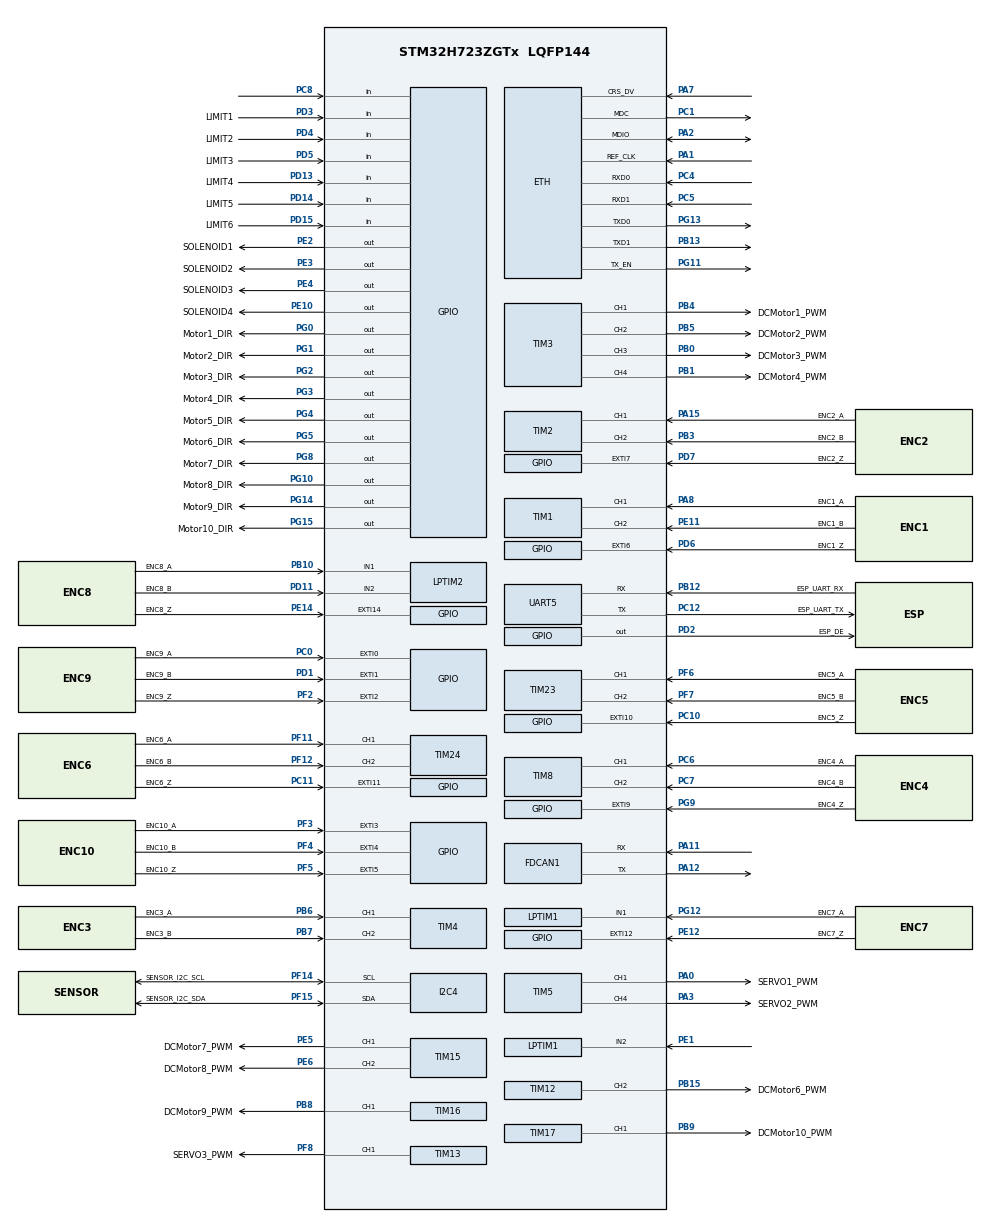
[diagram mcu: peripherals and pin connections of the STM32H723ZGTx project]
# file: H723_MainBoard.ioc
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CORTEX_M7.default_mode_Activation=1
Dma.Request0=UART5_RX
Dma.UART5_RX.0.Direction=DMA_PERIPH_TO_MEMORY
Dma.UART5_RX.0.EventEnable=DISABLE
Dma.UART5_RX.0.FIFOMode=DMA_FIFOMODE_DISABLE
Dma.UART5_RX.0.Instance=DMA1_Stream0
Dma.UART5_RX.0.MemDataAlignment=DMA_MDATAALIGN_BYTE
Dma.UART5_RX.0.MemInc=DMA_MINC_ENABLE
Dma.UART5_RX.0.Mode=DMA_CIRCULAR
Dma.UART5_RX.0.PeriphDataAlignment=DMA_PDATAALIGN_BYTE
Dma.UART5_RX.0.PeriphInc=DMA_PINC_DISABLE
Dma.UART5_RX.0.Polarity=HAL_DMAMUX_REQ_GEN_RISING
Dma.UART5_RX.0.Priority=DMA_PRIORITY_LOW
Dma.UART5_RX.0.RequestNumber=1
Dma.UART5_RX.0.SignalID=NONE
Dma.UART5_RX.0.SyncEnable=DISABLE
Dma.UART5_RX.0.SyncPolarity=HAL_DMAMUX_SYNC_NO_EVENT
Dma.UART5_RX.0.SyncRequestNumber=1
Dma.UART5_RX.0.SyncSignalID=NONE
ETH.MediaInterface=HAL_ETH_RMII_MODE
FDCAN1.CalculateBaudRateNominal=250000
FDCAN1.CalculateTimeBitNominal=4000
FDCAN1.CalculateTimeQuantumNominal=250.0
FDCAN1.NominalPrescaler=12
FDCAN1.NominalSyncJumpWidth=2
FDCAN1.NominalTimeSeg1=13
FDCAN1.NominalTimeSeg2=2
FDCAN1.RxFifo0ElmtsNbr=16
FDCAN1.StdFiltersNbr=1
I2C4.Timing=0x20303E5D
Mcu.Family=STM32H7
Mcu.Name=STM32H723ZGTx
Mcu.Package=LQFP144
NUCLEO-H723ZG.BUTTON=1
NUCLEO-H723ZG.LD1=false
NUCLEO-H723ZG.LD2=true
NUCLEO-H723ZG.LD3=true
NUCLEO-H723ZG.VCP=true
NVIC.DMA1_Stream0_IRQn=true\:0\:0\:false\:false\:true\:false\:true\:true
NVIC.EXTI15_10_IRQn=true\:0\:0\:false\:false\:true\:false\:true\:true
NVIC.PriorityGroup=NVIC_PRIORITYGROUP_4
NVIC.UART5_IRQn=true\:0\:0\:false\:false\:true\:true\:true\:true
PA0.GPIO_Label=SERVO1_PWM
PA0.Signal=S_TIM5_CH1
PA1.Mode=RMII
PA1.Signal=ETH_REF_CLK
PA11.Mode=FDCAN_Activate
PA11.Signal=FDCAN1_RX
PA12.Mode=FDCAN_Activate
PA12.Signal=FDCAN1_TX
PA13(JTMS/SWDIO).GPIO_Label=SWDIO
PA13(JTMS/SWDIO).Mode=Serial_Wire
PA13(JTMS/SWDIO).Signal=DEBUG_JTMS-SWDIO
PA14(JTCK/SWCLK).GPIO_Label=SWCLK
PA14(JTCK/SWCLK).Mode=Serial_Wire
PA14(JTCK/SWCLK).Signal=DEBUG_JTCK-SWCLK
PA15(JTDI).GPIO_Label=ENC2_A
PA15(JTDI).Signal=S_TIM2_CH1_ETR
PA2.Mode=RMII
PA2.Signal=ETH_MDIO
PA3.GPIO_Label=SERVO2_PWM
PA3.Signal=S_TIM5_CH4
PA7.Mode=RMII
PA7.Signal=ETH_CRS_DV
PA8.GPIO_Label=ENC1_A
PA8.Signal=S_TIM1_CH1
PB0.GPIO_Label=DCMotor3_PWM
PB0.Signal=S_TIM3_CH3
PB1.GPIO_Label=DCMotor4_PWM
PB1.Signal=S_TIM3_CH4
PB10.GPIO_Label=ENC8_A
PB10.Mode=Encoder_mode_occur1
PB10.Signal=LPTIM2_IN1
PB12.GPIO_Label=ESP_UART_RX
PB12.Mode=Asynchronous
PB12.Signal=UART5_RX
PB13.Mode=RMII
PB13.Signal=ETH_TXD1
PB15.GPIO_Label=DCMotor6_PWM
PB15.Signal=S_TIM12_CH2
PB3(JTDO/TRACESWO).GPIO_Label=ENC2_B
PB3(JTDO/TRACESWO).Signal=S_TIM2_CH2
PB4(NJTRST).GPIO_Label=DCMotor1_PWM
PB4(NJTRST).Signal=S_TIM3_CH1
PB5.GPIO_Label=DCMotor2_PWM
PB5.Signal=S_TIM3_CH2
PB6.GPIO_Label=ENC3_A
PB6.Signal=S_TIM4_CH1
PB7.GPIO_Label=ENC3_B
PB7.Signal=S_TIM4_CH2
PB8.GPIO_Label=DCMotor9_PWM
PB8.Signal=S_TIM16_CH1
PB9.GPIO_Label=DCMotor10_PWM
PB9.Signal=S_TIM17_CH1
PC0.GPIO_Label=ENC9_A
PC0.Signal=GPXTI0
PC1.Mode=RMII
PC1.Signal=ETH_MDC
PC10.GPIO_Label=ENC5_Z
PC10.Signal=GPXTI10
PC11.GPIO_Label=ENC6_Z
PC11.Signal=GPXTI11
PC12.GPIO_Label=ESP_UART_TX
PC12.Mode=Asynchronous
PC12.Signal=UART5_TX
PC14-OSC32_IN.Mode=LSE-External-Oscillator
PC14-OSC32_IN.Signal=RCC_OSC32_IN
PC15-OSC32_OUT.Mode=LSE-External-Oscillator
PC15-OSC32_OUT.Signal=RCC_OSC32_OUT
PC4.Mode=RMII
PC4.Signal=ETH_RXD0
PC5.Mode=RMII
PC5.Signal=ETH_RXD1
PC6.GPIO_Label=ENC4_A
PC6.Signal=S_TIM8_CH1
PC7.GPIO_Label=ENC4_B
PC7.Signal=S_TIM8_CH2
PC8.Signal=GPIO_Input
PD1.GPIO_Label=ENC9_B
PD1.Signal=GPXTI1
PD11.GPIO_Label=ENC8_B
PD11.Mode=Encoder_mode_occur1
PD11.Signal=LPTIM2_IN2
PD13.GPIO_Label=LIMIT4
PD13.GPIO_PuPd=GPIO_PULLUP
PD13.Signal=GPIO_Input
PD14.GPIO_Label=LIMIT5
PD14.GPIO_PuPd=GPIO_PULLUP
PD14.Signal=GPIO_Input
PD15.GPIO_Label=LIMIT6
PD15.GPIO_PuPd=GPIO_PULLUP
PD15.Signal=GPIO_Input
PD2.GPIO_Label=ESP_DE
PD2.Signal=GPIO_Output
PD3.GPIO_Label=LIMIT1
PD3.GPIO_PuPd=GPIO_PULLUP
PD3.Signal=GPIO_Input
PD4.GPIO_Label=LIMIT2
PD4.GPIO_PuPd=GPIO_PULLUP
PD4.Signal=GPIO_Input
PD5.GPIO_Label=LIMIT3
PD5.GPIO_PuPd=GPIO_PULLUP
PD5.Signal=GPIO_Input
PD6.GPIO_Label=ENC1_Z
PD6.GPIO_PuPd=GPIO_NOPULL
PD6.Signal=GPXTI6
PD7.GPIO_Label=ENC2_Z
PD7.Signal=GPXTI7
PD8.Signal=USART3_TX
PD9.Signal=USART3_RX
PE1.Mode=Encoder_mode_occur1
PE1.Signal=LPTIM1_IN2
PE10.GPIO_Label=SOLENOID4
PE10.Signal=GPIO_Output
PE11.GPIO_Label=ENC1_B
PE11.Signal=S_TIM1_CH2
PE12.GPIO_Label=ENC7_Z
PE12.Signal=GPXTI12
PE14.GPIO_Label=ENC8_Z
PE14.Signal=GPXTI14
PE2.GPIO_Label=SOLENOID1
PE2.Signal=GPIO_Output
PE3.GPIO_Label=SOLENOID2
PE3.Signal=GPIO_Output
PE4.GPIO_Label=SOLENOID3
PE4.Signal=GPIO_Output
PE5.GPIO_Label=DCMotor7_PWM
PE5.Signal=S_TIM15_CH1
PE6.GPIO_Label=DCMotor8_PWM
PE6.Signal=S_TIM15_CH2
PF11.GPIO_Label=ENC6_A
PF11.Mode=Encoder_Interface
PF11.Signal=TIM24_CH1
PF12.GPIO_Label=ENC6_B
PF12.Signal=S_TIM24_CH2
PF14.GPIO_Label=SENSOR_I2C_SCL
PF14.Mode=I2C
PF14.Signal=I2C4_SCL
PF15.GPIO_Label=SENSOR_I2C_SDA
PF15.Mode=I2C
PF15.Signal=I2C4_SDA
PF2.GPIO_Label=ENC9_Z
PF2.Signal=GPXTI2
PF3.GPIO_Label=ENC10_A
PF3.Signal=GPXTI3
PF4.GPIO_Label=ENC10_B
PF4.Signal=GPXTI4
PF5.GPIO_Label=ENC10_Z
PF5.Signal=GPXTI5
PF6.GPIO_Label=ENC5_A
PF6.Mode=Encoder_Interface
PF6.Signal=TIM23_CH1
PF7.GPIO_Label=ENC5_B
PF7.Signal=S_TIM23_CH2
PF8.GPIO_Label=SERVO3_PWM
PF8.Signal=S_TIM13_CH1
PG0.GPIO_Label=Motor1_DIR
PG0.Signal=GPIO_Output
PG1.GPIO_Label=Motor2_DIR
PG1.Signal=GPIO_Output
PG10.GPIO_Label=Motor8_DIR
PG10.Signal=GPIO_Output
PG11.Mode=RMII
PG11.Signal=ETH_TX_EN
PG12.GPIO_Label=ENC7_A
PG12.Mode=Encoder_mode_occur1
PG12.Signal=LPTIM1_IN1
PG13.Mode=RMII
PG13.Signal=ETH_TXD0
PG14.GPIO_Label=Motor9_DIR
PG14.Signal=GPIO_Output
PG15.GPIO_Label=Motor10_DIR
PG15.Signal=GPIO_Output
PG2.GPIO_Label=Motor3_DIR
PG2.Signal=GPIO_Output
PG3.GPIO_Label=Motor4_DIR
PG3.Signal=GPIO_Output
PG4.GPIO_Label=Motor5_DIR
PG4.Signal=GPIO_Output
PG5.GPIO_Label=Motor6_DIR
PG5.Signal=GPIO_Output
PG8.GPIO_Label=Motor7_DIR
PG8.Signal=GPIO_Output
PG9.GPIO_Label=ENC4_Z
PG9.Signal=GPXTI9
ProjectManager.HeapSize=0x200
ProjectManager.StackSize=0x400
ProjectManager.TargetToolchain=CMake
RCC.ADCFreq_Value=608000000
RCC.APB1Freq_Value=48000000
RCC.APB2Freq_Value=48000000
RCC.APB3Freq_Value=48000000
RCC.APB4Freq_Value=48000000
RCC.CortexFreq_Value=192000000
RCC.D1PPRE=RCC_APB3_DIV2
RCC.D2PPRE1=RCC_APB1_DIV2
RCC.D2PPRE2=RCC_APB2_DIV2
RCC.D3PPRE=RCC_APB4_DIV2
RCC.DIVM1=4
RCC.DIVM2=1
RCC.DIVN1=12
RCC.DIVN2=19
RCC.DIVP1=1
RCC.DIVQ1=4
RCC.HCLKFreq_Value=96000000
RCC.HPRE=RCC_HCLK_DIV2
RCC.HSE_VALUE=8000000
RCC.PLLFRACN=0
RCC.SYSCLKFreq_VALUE=192000000
RCC.SYSCLKSource=RCC_SYSCLKSOURCE_PLLCLK
RCC.USBCLockSelection=RCC_USBCLKSOURCE_HSI48
RCC.USBFreq_Value=48000000
SH.S_TIM12_CH2.0=TIM12_CH2,PWM Generation2 CH2
SH.S_TIM13_CH1.0=TIM13_CH1,PWM Generation1 CH1
SH.S_TIM15_CH1.0=TIM15_CH1,PWM Generation1 CH1
SH.S_TIM15_CH2.0=TIM15_CH2,PWM Generation2 CH2
SH.S_TIM16_CH1.0=TIM16_CH1,PWM Generation1 CH1
SH.S_TIM17_CH1.0=TIM17_CH1,PWM Generation1 CH1
SH.S_TIM1_CH1.0=TIM1_CH1,Encoder_Interface
SH.S_TIM1_CH2.0=TIM1_CH2,Encoder_Interface
SH.S_TIM23_CH2.0=TIM23_CH2,Encoder_Interface
SH.S_TIM24_CH2.0=TIM24_CH2,Encoder_Interface
SH.S_TIM2_CH1_ETR.0=TIM2_CH1,Encoder_Interface
SH.S_TIM2_CH2.0=TIM2_CH2,Encoder_Interface
SH.S_TIM3_CH1.0=TIM3_CH1,PWM Generation1 CH1
SH.S_TIM3_CH2.0=TIM3_CH2,PWM Generation2 CH2
SH.S_TIM3_CH3.0=TIM3_CH3,PWM Generation3 CH3
SH.S_TIM3_CH4.0=TIM3_CH4,PWM Generation4 CH4
SH.S_TIM4_CH1.0=TIM4_CH1,Encoder_Interface
SH.S_TIM4_CH2.0=TIM4_CH2,Encoder_Interface
SH.S_TIM5_CH1.0=TIM5_CH1,PWM Generation1 CH1
SH.S_TIM5_CH4.0=TIM5_CH4,PWM Generation4 CH4
SH.S_TIM8_CH1.0=TIM8_CH1,Encoder_Interface
SH.S_TIM8_CH2.0=TIM8_CH2,Encoder_Interface
TIM12.Channel-PWM\ Generation1\ CH1=TIM_CHANNEL_1
TIM12.Channel-PWM\ Generation2\ CH2=TIM_CHANNEL_2
TIM13.Channel=TIM_CHANNEL_1
TIM15.Channel-PWM\ Generation1\ CH1=TIM_CHANNEL_1
TIM15.Channel-PWM\ Generation2\ CH2=TIM_CHANNEL_2
TIM16.Channel=TIM_CHANNEL_1
TIM17.Channel=TIM_CHANNEL_1
TIM3.Channel-PWM\ Generation1\ CH1=TIM_CHANNEL_1
TIM3.Channel-PWM\ Generation2\ CH2=TIM_CHANNEL_2
TIM3.Channel-PWM\ Generation3\ CH3=TIM_CHANNEL_3
TIM3.Channel-PWM\ Generation4\ CH4=TIM_CHANNEL_4
TIM5.Channel-PWM\ Generation1\ CH1=TIM_CHANNEL_1
TIM5.Channel-PWM\ Generation4\ CH4=TIM_CHANNEL_4
VP_MEMORYMAP_VS_MEMORYMAP.Mode=CurAppReg
VP_NUCLEO-H723ZG_VS_BSP_COMMON.Mode=COMMON
VP_TIM13_VS_ClockSourceINT.Mode=Enable_Timer
VP_TIM16_VS_ClockSourceINT.Mode=Enable_Timer
VP_TIM17_VS_ClockSourceINT.Mode=Enable_Timer
board=NUCLEO-H723ZG

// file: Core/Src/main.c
/* USER CODE BEGIN Header */
/**
  ******************************************************************************
  * @file           : main.c
  * @brief          : Main program body
  ******************************************************************************
  * @attention
  *
  * Copyright (c) 2026 STMicroelectronics.
  * All rights reserved.
  *
  * This software is licensed under terms that can be found in the LICENSE file
  * in the root directory of this software component.
  * If no LICENSE file comes with this software, it is provided AS-IS.
  *
  ******************************************************************************
  */
/* USER CODE END Header */
#include "main.h"
#include "dma.h"
#include "eth.h"
#include "fdcan.h"
#include "i2c.h"
#include "lptim.h"
#include "tim.h"
#include "usart.h"
#include "gpio.h"

COM_InitTypeDef BspCOMInit;

/* USER CODE BEGIN PV */

volatile uint32_t can_rx_count = 0;
volatile uint32_t can_rx_id = 0;
volatile uint32_t can_rx_dlc = 0;
volatile uint8_t can_rx_data[8] = {0};
volatile uint32_t can_psr = 0;
volatile uint32_t can_ecr = 0;
volatile uint32_t can_clock = 0;
volatile uint32_t can_error_events = 0;
volatile uint32_t can_last_error = 0;
volatile uint32_t can_rx_low_samples = 0;
volatile uint32_t can_rx_sampled_edges = 0;
/* USER CODE END PV */

void SystemClock_Config(void);
static void MPU_Config(void);

int main(void)
{

  /* MPU Configuration--------------------------------------------------------*/
  MPU_Config();

  /* MCU Configuration--------------------------------------------------------*/

  /* Reset of all peripherals, Initializes the Flash interface and the Systick. */
  HAL_Init();

  /* Configure the system clock */
  SystemClock_Config();

  /* Initialize all configured peripherals */
  MX_GPIO_Init();
  MX_DMA_Init();
  MX_ETH_Init();
  MX_TIM3_Init();
  MX_TIM12_Init();
  MX_TIM15_Init();
  MX_TIM16_Init();
  MX_I2C4_Init();
  MX_LPTIM2_Init();
  MX_TIM1_Init();
  MX_TIM2_Init();
  MX_TIM4_Init();
  MX_TIM5_Init();
  MX_TIM8_Init();
  MX_TIM13_Init();
  MX_TIM17_Init();
  MX_TIM23_Init();
  MX_TIM24_Init();
  MX_UART5_Init();
  MX_FDCAN1_Init();
  /* USER CODE BEGIN 2 */

FDCAN_FilterTypeDef filter = {0};

filter.IdType = FDCAN_STANDARD_ID;
filter.FilterIndex = 0;
filter.FilterType = FDCAN_FILTER_MASK;
filter.FilterConfig = FDCAN_FILTER_TO_RXFIFO0;
filter.FilterID1 = 0x000;
filter.FilterID2 = 0x000;

if (HAL_FDCAN_ConfigFilter(&hfdcan1, &filter) != HAL_OK)
{
    Error_Handler();
}
if (HAL_FDCAN_ConfigGlobalFilter(&hfdcan1,
                                 FDCAN_REJECT,
                                 FDCAN_REJECT,
                                 FDCAN_REJECT_REMOTE,
                                 FDCAN_REJECT_REMOTE) != HAL_OK)
{
    Error_Handler();
}
if (HAL_FDCAN_Start(&hfdcan1) != HAL_OK)
{
    Error_Handler();
}

  /* USER CODE END 2 */

  /* Initialize leds */
  BSP_LED_Init(LED_YELLOW);
  BSP_LED_Init(LED_RED);

  /* Initialize USER push-button, will be used to trigger an interrupt each time it's pressed.*/
  BSP_PB_Init(BUTTON_USER, BUTTON_MODE_EXTI);

  /* Initialize COM1 port (115200, 8 bits (7-bit data + 1 stop bit), no parity */
  BspCOMInit.BaudRate   = 115200;
  BspCOMInit.WordLength = COM_WORDLENGTH_8B;
  BspCOMInit.StopBits   = COM_STOPBITS_1;
  BspCOMInit.Parity     = COM_PARITY_NONE;
  BspCOMInit.HwFlowCtl  = COM_HWCONTROL_NONE;
  if (BSP_COM_Init(COM1, &BspCOMInit) != BSP_ERROR_NONE)
  {
    Error_Handler();
  }

  /* Infinite loop */
  /* USER CODE BEGIN WHILE */
  /* CAN serial monitor: ST-LINK virtual COM, USART3 PD8/PD9. */
  setvbuf(stdout, NULL, _IONBF, 0);
  printf("\r\nH723 CAN serial monitor: Classic CAN, Normal, 250000 bps\r\n");
  printf("Serial: 115200 8N1, no flow control; CAN RX: PA11, TX: PA12\r\n");
  uint32_t last_rx_print = 0;
  uint32_t last_printed_count = 0;
  uint32_t last_status_print = 0;
  uint32_t last_rx_level = (GPIOA->IDR & GPIO_PIN_11) != 0U;
  while (1)
  {

    /* USER CODE END WHILE */

    /* USER CODE BEGIN 3 */
    /* Passive sampling: this is not a complete waveform capture. */
    uint32_t rx_level = (GPIOA->IDR & GPIO_PIN_11) != 0U;
    if (rx_level == 0U && can_rx_low_samples != UINT32_MAX)
    {
      can_rx_low_samples++;
    }
    if (rx_level != last_rx_level && can_rx_sampled_edges != UINT32_MAX)
    {
      can_rx_sampled_edges++;
    }
    last_rx_level = rx_level;

    if (HAL_FDCAN_GetRxFifoFillLevel(&hfdcan1, FDCAN_RX_FIFO0) > 0U)
    {
      FDCAN_RxHeaderTypeDef rxHeader;
      uint8_t rxData[8] = {0};
      if (HAL_FDCAN_GetRxMessage(&hfdcan1, FDCAN_RX_FIFO0,
                                &rxHeader, rxData) == HAL_OK)
      {
        can_rx_count++;
        can_rx_id = rxHeader.Identifier;
        can_rx_dlc = rxHeader.DataLength;
        for (uint32_t i = 0; i < 8U; i++)
        {
          can_rx_data[i] = (i < can_rx_dlc) ? rxData[i] : 0U;
        }
      }
    }

    /* PSR.LEC/DLEC become 7 after reading; ECR.CEL clears on read. */
    can_psr = hfdcan1.Instance->PSR;
    can_ecr = hfdcan1.Instance->ECR;
    uint32_t errors = (can_ecr & FDCAN_ECR_CEL) >> FDCAN_ECR_CEL_Pos;
    if (UINT32_MAX - can_error_events < errors)
    {
      can_error_events = UINT32_MAX;
    }
    else
    {
      can_error_events += errors;
    }
    uint32_t lec = can_psr & FDCAN_PSR_LEC;
    if (lec >= 1U && lec <= 6U)
    {
      can_last_error = lec;
    }
    can_clock = HAL_RCCEx_GetPeriphCLKFreq(RCC_PERIPHCLK_FDCAN);

    /* Log the latest frame at most every 100 ms; keep polling all frames. */
    uint32_t now = HAL_GetTick();
    if (can_rx_count != last_printed_count && now - last_rx_print >= 100U)
    {
      last_rx_print = now;
      last_printed_count = can_rx_count;
      printf("RX count=%lu ID=0x%03lX DLC=%lu DATA=",
             (unsigned long)can_rx_count, (unsigned long)can_rx_id,
             (unsigned long)can_rx_dlc);
      for (uint32_t i = 0; i < can_rx_dlc && i < 8U; i++)
      {
        printf("%02X ", (unsigned int)can_rx_data[i]);
      }
      printf("\r\n");
    }
    if (now - last_status_print >= 1000U)
    {
      last_status_print = now;
      printf("STATUS rx=%lu TEC=%lu REC=%lu PSR=0x%08lX FIFO=%lu CLK=%lu\r\n",
             (unsigned long)can_rx_count,
             (unsigned long)(can_ecr & FDCAN_ECR_TEC),
             (unsigned long)((can_ecr & FDCAN_ECR_REC) >> FDCAN_ECR_REC_Pos),
             (unsigned long)can_psr,
             (unsigned long)HAL_FDCAN_GetRxFifoFillLevel(&hfdcan1, FDCAN_RX_FIFO0),
             (unsigned long)can_clock);
      printf("DIAG RXpin=%lu LOW=%lu EDGES=%lu ERR=%lu LAST_LEC=%lu CCCR=0x%08lX HAL=0x%08lX\r\n",
             (unsigned long)rx_level,
             (unsigned long)can_rx_low_samples,
             (unsigned long)can_rx_sampled_edges,
             (unsigned long)can_error_events,
             (unsigned long)can_last_error,
             (unsigned long)hfdcan1.Instance->CCCR,
             (unsigned long)HAL_FDCAN_GetError(&hfdcan1));
    }
  }
  /* USER CODE END 3 */
}

void SystemClock_Config(void)
{
  RCC_OscInitTypeDef RCC_OscInitStruct = {0};
  RCC_ClkInitTypeDef RCC_ClkInitStruct = {0};

  /** Supply configuration update enable
  */
  HAL_PWREx_ConfigSupply(PWR_LDO_SUPPLY);

  /** Configure the main internal regulator output voltage
  */
  __HAL_PWR_VOLTAGESCALING_CONFIG(PWR_REGULATOR_VOLTAGE_SCALE2);

  while(!__HAL_PWR_GET_FLAG(PWR_FLAG_VOSRDY)) {}

  /** Initializes the RCC Oscillators according to the specified parameters
  * in the RCC_OscInitTypeDef structure.
  */
  RCC_OscInitStruct.OscillatorType = RCC_OSCILLATORTYPE_HSI;
  RCC_OscInitStruct.HSIState = RCC_HSI_DIV1;
  RCC_OscInitStruct.HSICalibrationValue = 64;
  RCC_OscInitStruct.PLL.PLLState = RCC_PLL_ON;
  RCC_OscInitStruct.PLL.PLLSource = RCC_PLLSOURCE_HSI;
  RCC_OscInitStruct.PLL.PLLM = 4;
  RCC_OscInitStruct.PLL.PLLN = 12;
  RCC_OscInitStruct.PLL.PLLP = 1;
  RCC_OscInitStruct.PLL.PLLQ = 4;
  RCC_OscInitStruct.PLL.PLLR = 2;
  RCC_OscInitStruct.PLL.PLLRGE = RCC_PLL1VCIRANGE_3;
  RCC_OscInitStruct.PLL.PLLVCOSEL = RCC_PLL1VCOWIDE;
  RCC_OscInitStruct.PLL.PLLFRACN = 0;
  if (HAL_RCC_OscConfig(&RCC_OscInitStruct) != HAL_OK)
  {
    Error_Handler();
  }

  /** Initializes the CPU, AHB and APB buses clocks
  */
  RCC_ClkInitStruct.ClockType = RCC_CLOCKTYPE_HCLK|RCC_CLOCKTYPE_SYSCLK
                              |RCC_CLOCKTYPE_PCLK1|RCC_CLOCKTYPE_PCLK2
                              |RCC_CLOCKTYPE_D3PCLK1|RCC_CLOCKTYPE_D1PCLK1;
  RCC_ClkInitStruct.SYSCLKSource = RCC_SYSCLKSOURCE_PLLCLK;
  RCC_ClkInitStruct.SYSCLKDivider = RCC_SYSCLK_DIV1;
  RCC_ClkInitStruct.AHBCLKDivider = RCC_HCLK_DIV2;
  RCC_ClkInitStruct.APB3CLKDivider = RCC_APB3_DIV2;
  RCC_ClkInitStruct.APB1CLKDivider = RCC_APB1_DIV2;
  RCC_ClkInitStruct.APB2CLKDivider = RCC_APB2_DIV2;
  RCC_ClkInitStruct.APB4CLKDivider = RCC_APB4_DIV2;

  if (HAL_RCC_ClockConfig(&RCC_ClkInitStruct, FLASH_LATENCY_1) != HAL_OK)
  {
    Error_Handler();
  }
}

 /* MPU Configuration */

void MPU_Config(void)
{
  MPU_Region_InitTypeDef MPU_InitStruct = {0};

  /* Disables the MPU */
  HAL_MPU_Disable();

  /** Initializes and configures the Region and the memory to be protected
  */
  MPU_InitStruct.Enable = MPU_REGION_ENABLE;
  MPU_InitStruct.Number = MPU_REGION_NUMBER0;
  MPU_InitStruct.BaseAddress = 0x0;
  MPU_InitStruct.Size = MPU_REGION_SIZE_4GB;
  MPU_InitStruct.SubRegionDisable = 0x87;
  MPU_InitStruct.TypeExtField = MPU_TEX_LEVEL0;
  MPU_InitStruct.AccessPermission = MPU_REGION_NO_ACCESS;
  MPU_InitStruct.DisableExec = MPU_INSTRUCTION_ACCESS_DISABLE;
  MPU_InitStruct.IsShareable = MPU_ACCESS_SHAREABLE;
  MPU_InitStruct.IsCacheable = MPU_ACCESS_NOT_CACHEABLE;
  MPU_InitStruct.IsBufferable = MPU_ACCESS_NOT_BUFFERABLE;

  HAL_MPU_ConfigRegion(&MPU_InitStruct);
  /* Enables the MPU */
  HAL_MPU_Enable(MPU_PRIVILEGED_DEFAULT);

}

void Error_Handler(void)
{
  __disable_irq();
  while (1)
  {
  }
}
